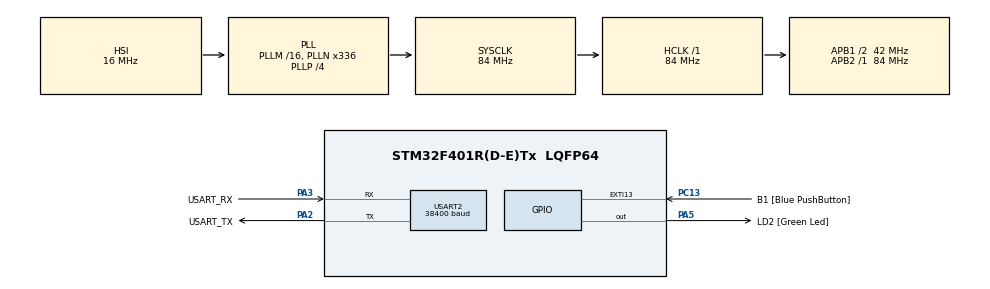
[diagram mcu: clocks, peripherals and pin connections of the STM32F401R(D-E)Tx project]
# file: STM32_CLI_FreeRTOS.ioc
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Dma.Request0=USART2_RX
Dma.Request1=USART2_TX
Dma.USART2_RX.0.Direction=DMA_PERIPH_TO_MEMORY
Dma.USART2_RX.0.FIFOMode=DMA_FIFOMODE_DISABLE
Dma.USART2_RX.0.Instance=DMA1_Stream5
Dma.USART2_RX.0.MemDataAlignment=DMA_MDATAALIGN_BYTE
Dma.USART2_RX.0.MemInc=DMA_MINC_ENABLE
Dma.USART2_RX.0.Mode=DMA_CIRCULAR
Dma.USART2_RX.0.PeriphDataAlignment=DMA_PDATAALIGN_BYTE
Dma.USART2_RX.0.PeriphInc=DMA_PINC_DISABLE
Dma.USART2_RX.0.Priority=DMA_PRIORITY_MEDIUM
Dma.USART2_TX.1.Direction=DMA_MEMORY_TO_PERIPH
Dma.USART2_TX.1.FIFOMode=DMA_FIFOMODE_DISABLE
Dma.USART2_TX.1.Instance=DMA1_Stream6
Dma.USART2_TX.1.MemDataAlignment=DMA_MDATAALIGN_BYTE
Dma.USART2_TX.1.MemInc=DMA_MINC_ENABLE
Dma.USART2_TX.1.Mode=DMA_NORMAL
Dma.USART2_TX.1.PeriphDataAlignment=DMA_PDATAALIGN_BYTE
Dma.USART2_TX.1.PeriphInc=DMA_PINC_DISABLE
Dma.USART2_TX.1.Priority=DMA_PRIORITY_MEDIUM
FREERTOS.MEMORY_ALLOCATION=2
FREERTOS.Tasks01=defaultTask,-3,128,StartDefaultTask,Default,NULL,Static,defaultTaskBuffer,defaultTaskControlBlock
FREERTOS.configGENERATE_RUN_TIME_STATS=1
FREERTOS.configUSE_STATS_FORMATTING_FUNCTIONS=1
FREERTOS.configUSE_TRACE_FACILITY=1
Mcu.Family=STM32F4
Mcu.Name=STM32F401R(D-E)Tx
Mcu.Package=LQFP64
NVIC.DMA1_Stream5_IRQn=true\:5\:0\:false\:false\:true\:true\:false\:true
NVIC.DMA1_Stream6_IRQn=true\:5\:0\:false\:false\:true\:true\:false\:true
NVIC.EXTI15_10_IRQn=true\:5\:0\:false\:false\:true\:true\:true\:true
NVIC.PriorityGroup=NVIC_PRIORITYGROUP_4
NVIC.TIM1_TRG_COM_TIM11_IRQn=true\:5\:0\:false\:false\:true\:true\:true\:true
NVIC.USART2_IRQn=true\:5\:0\:false\:false\:true\:true\:true\:true
PA13.GPIO_Label=TMS
PA13.Mode=Serial_Wire
PA13.Signal=SYS_JTMS-SWDIO
PA14.GPIO_Label=TCK
PA14.Mode=Serial_Wire
PA14.Signal=SYS_JTCK-SWCLK
PA2.GPIO_Label=USART_TX
PA2.GPIO_Mode=GPIO_MODE_AF_PP
PA2.GPIO_PuPd=GPIO_NOPULL
PA2.GPIO_Speed=GPIO_SPEED_FREQ_LOW
PA2.Mode=Asynchronous
PA2.Signal=USART2_TX
PA3.GPIO_Label=USART_RX
PA3.GPIO_Mode=GPIO_MODE_AF_PP
PA3.GPIO_PuPd=GPIO_NOPULL
PA3.GPIO_Speed=GPIO_SPEED_FREQ_LOW
PA3.Mode=Asynchronous
PA3.Signal=USART2_RX
PA5.GPIO_Label=LD2 [Green Led]
PA5.GPIO_Mode=GPIO_MODE_OUTPUT_PP
PA5.GPIO_PuPd=GPIO_NOPULL
PA5.GPIO_Speed=GPIO_SPEED_FREQ_LOW
PA5.Signal=GPIO_Output
PC13-ANTI_TAMP.GPIO_Label=B1 [Blue PushButton]
PC13-ANTI_TAMP.GPIO_ModeDefaultEXTI=GPIO_MODE_IT_FALLING
PC13-ANTI_TAMP.GPIO_PuPd=GPIO_NOPULL
PC13-ANTI_TAMP.Signal=GPXTI13
ProjectManager.HeapSize=0x200
ProjectManager.StackSize=0x1000
ProjectManager.TargetToolchain=STM32CubeIDE
RCC.48MHZClocksFreq_Value=48000000
RCC.AHBFreq_Value=84000000
RCC.APB1CLKDivider=RCC_HCLK_DIV2
RCC.APB1Freq_Value=42000000
RCC.APB1TimFreq_Value=84000000
RCC.APB2Freq_Value=84000000
RCC.APB2TimFreq_Value=84000000
RCC.CortexFreq_Value=84000000
RCC.HCLKFreq_Value=84000000
RCC.HSE_VALUE=8000000
RCC.HSI_VALUE=16000000
RCC.LSE_VALUE=32768
RCC.PLLN=336
RCC.PLLP=RCC_PLLP_DIV4
RCC.PLLQ=7
RCC.SYSCLKFreq_VALUE=84000000
RCC.SYSCLKSource=RCC_SYSCLKSOURCE_PLLCLK
RCC.VCOOutputFreq_Value=336000000
TIM11.AutoReloadPreload=TIM_AUTORELOAD_PRELOAD_ENABLE
TIM11.Period=100-9
TIM11.Prescaler=84-1
USART2.BaudRate=38400
USART2.VirtualMode=VM_ASYNC
VP_FREERTOS_VS_CMSIS_V1.Mode=CMSIS_V1
VP_TIM11_VS_ClockSourceINT.Mode=Enable_Timer
board=NUCLEO-F401RE

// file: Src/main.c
/* USER CODE BEGIN Header */
/**
  ******************************************************************************
  * @file           : main.c
  * @brief          : Main program body
  ******************************************************************************
  * @attention
  *
  * <h2><center>&copy; Copyright (c) 2019 STMicroelectronics.
  * All rights reserved.</center></h2>
  *
  * This software component is licensed by ST under BSD 3-Clause license,
  * the "License"; You may not use this file except in compliance with the
  * License. You may obtain a copy of the License at:
  *                        opensource.org/licenses/BSD-3-Clause
  *
  ******************************************************************************
  */
/* USER CODE END Header */

#include "main.h"
#include "cmsis_os.h"
#include "dma.h"
#include "tim.h"
#include "usart.h"
#include "gpio.h"

/* USER CODE BEGIN Includes */
#include "cli_uart_interface.h"
/* USER CODE END Includes */

void SystemClock_Config(void);
void MX_FREERTOS_Init(void);

int main(void)
{

  /* MCU Configuration--------------------------------------------------------*/

  /* Reset of all peripherals, Initializes the Flash interface and the Systick. */
  HAL_Init();

  /* Configure the system clock */
  SystemClock_Config();

  /* Initialize all configured peripherals */
  MX_GPIO_Init();
  MX_DMA_Init();
  MX_USART2_UART_Init();
  MX_TIM11_Init();
  /* USER CODE BEGIN 2 */

#if (TRC_USE_TRACEALYZER_RECORDER == 1)
  vTraceEnable(TRC_START);
#endif

  CLI_UART_Thread_Add();

  /* USER CODE END 2 */

  /* Call init function for freertos objects (in freertos.c) */
  MX_FREERTOS_Init();

  /* Start scheduler */
  osKernelStart();

  /* We should never get here as control is now taken by the scheduler */

  /* Infinite loop */
  while (1)
  {

  }
}

void SystemClock_Config(void)
{
  RCC_OscInitTypeDef RCC_OscInitStruct = {0};
  RCC_ClkInitTypeDef RCC_ClkInitStruct = {0};

  /** Configure the main internal regulator output voltage
  */
  __HAL_RCC_PWR_CLK_ENABLE();
  __HAL_PWR_VOLTAGESCALING_CONFIG(PWR_REGULATOR_VOLTAGE_SCALE2);
  /** Initializes the CPU, AHB and APB busses clocks
  */
  RCC_OscInitStruct.OscillatorType = RCC_OSCILLATORTYPE_HSI;
  RCC_OscInitStruct.HSIState = RCC_HSI_ON;
  RCC_OscInitStruct.HSICalibrationValue = RCC_HSICALIBRATION_DEFAULT;
  RCC_OscInitStruct.PLL.PLLState = RCC_PLL_ON;
  RCC_OscInitStruct.PLL.PLLSource = RCC_PLLSOURCE_HSI;
  RCC_OscInitStruct.PLL.PLLM = 16;
  RCC_OscInitStruct.PLL.PLLN = 336;
  RCC_OscInitStruct.PLL.PLLP = RCC_PLLP_DIV4;
  RCC_OscInitStruct.PLL.PLLQ = 7;
  if (HAL_RCC_OscConfig(&RCC_OscInitStruct) != HAL_OK)
  {
    Error_Handler();
  }
  /** Initializes the CPU, AHB and APB busses clocks
  */
  RCC_ClkInitStruct.ClockType = RCC_CLOCKTYPE_HCLK|RCC_CLOCKTYPE_SYSCLK
                              |RCC_CLOCKTYPE_PCLK1|RCC_CLOCKTYPE_PCLK2;
  RCC_ClkInitStruct.SYSCLKSource = RCC_SYSCLKSOURCE_PLLCLK;
  RCC_ClkInitStruct.AHBCLKDivider = RCC_SYSCLK_DIV1;
  RCC_ClkInitStruct.APB1CLKDivider = RCC_HCLK_DIV2;
  RCC_ClkInitStruct.APB2CLKDivider = RCC_HCLK_DIV1;

  if (HAL_RCC_ClockConfig(&RCC_ClkInitStruct, FLASH_LATENCY_2) != HAL_OK)
  {
    Error_Handler();
  }
}

void Error_Handler(void)
{
}

/************************ (C) COPYRIGHT STMicroelectronics *****END OF FILE****/

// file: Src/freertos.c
/* USER CODE BEGIN Header */
/**
  ******************************************************************************
  * File Name          : freertos.c
  * Description        : Code for freertos applications
  ******************************************************************************
  * @attention
  *
  * <h2><center>&copy; Copyright (c) 2019 STMicroelectronics.
  * All rights reserved.</center></h2>
  *
  * This software component is licensed by ST under Ultimate Liberty license
  * SLA0044, the "License"; You may not use this file except in compliance with
  * the License. You may obtain a copy of the License at:
  *                             www.st.com/SLA0044
  *
  ******************************************************************************
  */
/* USER CODE END Header */

#include "FreeRTOS.h"
#include "task.h"
#include "main.h"
#include "cmsis_os.h"

/* USER CODE BEGIN Variables */

extern uint32_t Stat_Time_Counter;
extern TIM_HandleTypeDef htim11;

/* USER CODE END Variables */
osThreadId defaultTaskHandle;
uint32_t defaultTaskBuffer[ 128 ];
osStaticThreadDef_t defaultTaskControlBlock;

void StartDefaultTask(void const * argument);

void MX_FREERTOS_Init(void); /* (MISRA C 2004 rule 8.1) */

/* GetIdleTaskMemory prototype (linked to static allocation support) */
void vApplicationGetIdleTaskMemory( StaticTask_t **ppxIdleTaskTCBBuffer, StackType_t **ppxIdleTaskStackBuffer, uint32_t *pulIdleTaskStackSize );

/* Hook prototypes */
void configureTimerForRunTimeStats(void);
unsigned long getRunTimeCounterValue(void);

/* USER CODE BEGIN 1 */
/* Functions needed when configGENERATE_RUN_TIME_STATS is on */
__weak void configureTimerForRunTimeStats(void)
{
    HAL_TIM_Base_Start_IT(&htim11);
}

__weak unsigned long getRunTimeCounterValue(void)
{
	return Stat_Time_Counter;
}
/* USER CODE END 1 */

/* USER CODE BEGIN GET_IDLE_TASK_MEMORY */
static StaticTask_t xIdleTaskTCBBuffer;
static StackType_t xIdleStack[configMINIMAL_STACK_SIZE];

void vApplicationGetIdleTaskMemory( StaticTask_t **ppxIdleTaskTCBBuffer, StackType_t **ppxIdleTaskStackBuffer, uint32_t *pulIdleTaskStackSize )
{
  *ppxIdleTaskTCBBuffer = &xIdleTaskTCBBuffer;
  *ppxIdleTaskStackBuffer = &xIdleStack[0];
  *pulIdleTaskStackSize = configMINIMAL_STACK_SIZE;
  /* place for user code */
}
/* USER CODE END GET_IDLE_TASK_MEMORY */

void MX_FREERTOS_Init(void) {

  /* Create the thread(s) */
  /* definition and creation of defaultTask */
  osThreadStaticDef(defaultTask, StartDefaultTask, osPriorityIdle, 0, 128, defaultTaskBuffer, &defaultTaskControlBlock);
  defaultTaskHandle = osThreadCreate(osThread(defaultTask), NULL);

}

void StartDefaultTask(void const * argument)
{

  /* USER CODE BEGIN StartDefaultTask */

  /* Infinite loop */
  for(;;)
  {
	HAL_GPIO_TogglePin(LD2_GPIO_Port, LD2_Pin);
    osDelay(200);
  }
  /* USER CODE END StartDefaultTask */
}

/************************ (C) COPYRIGHT STMicroelectronics *****END OF FILE****/
